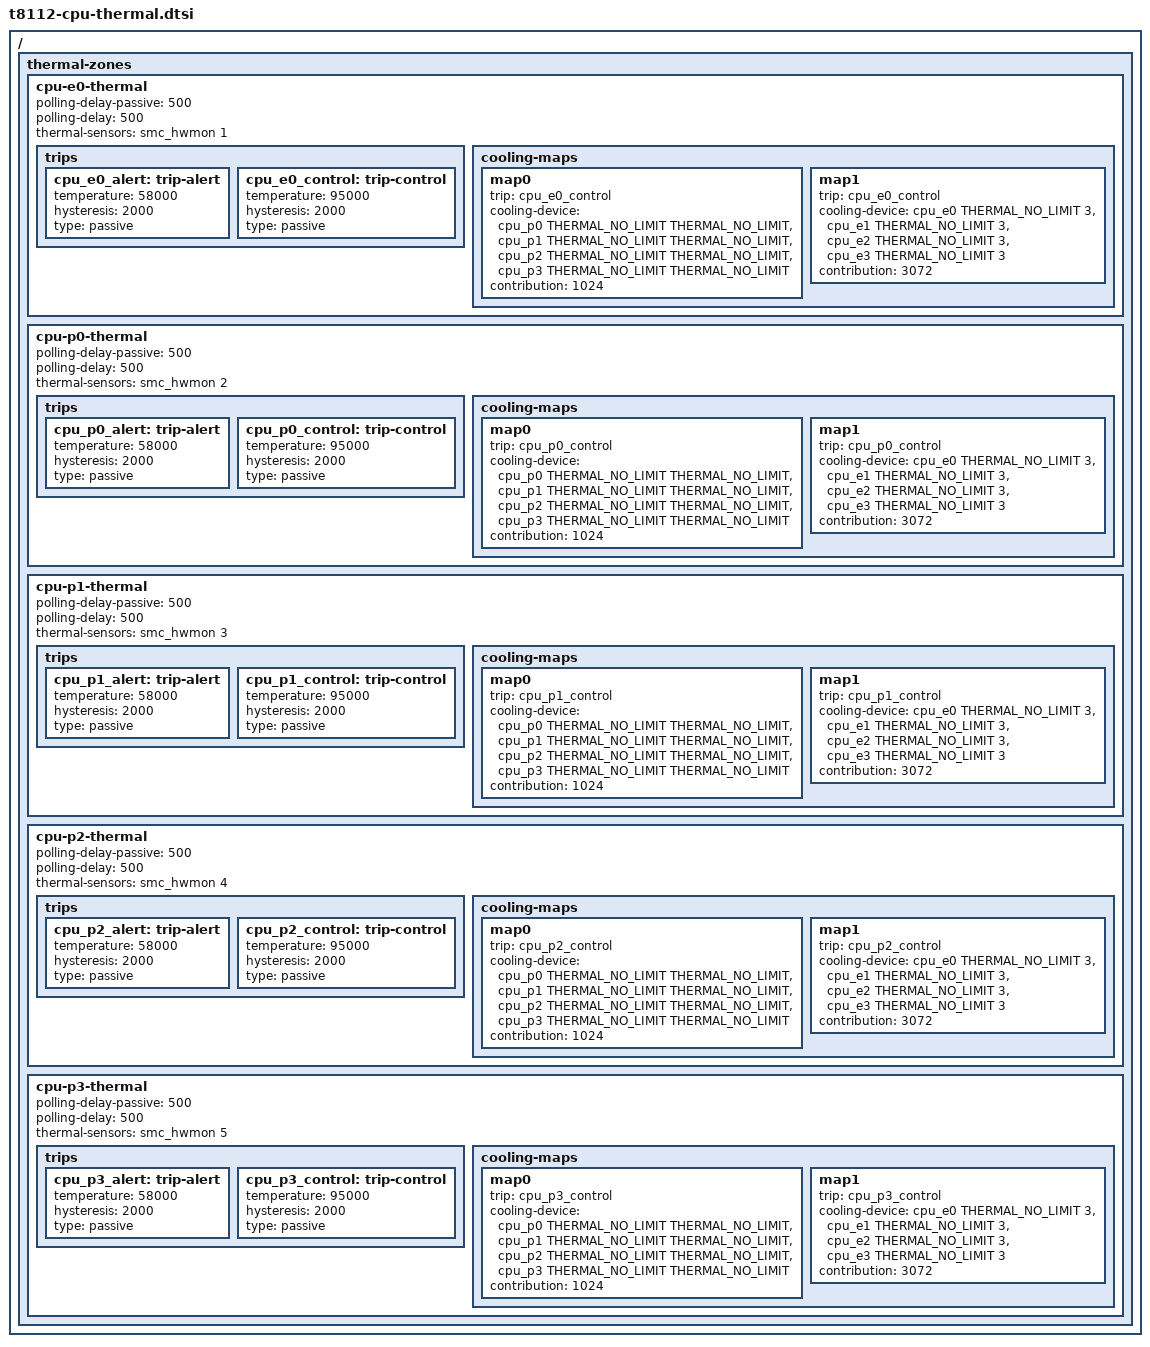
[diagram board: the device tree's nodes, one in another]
// SPDX-License-Identifier: GPL-2.0+ OR MIT
/*
 * CPU thermal zones of the fanless T8112 (M2) MacBook Airs.
 *
 * Each zone reads one SoC die key from the SMC hwmon: the T8112 SMC
 * reports them on every board, so t8112.dtsi lists them first among the
 * temperature channels and their indices are the same on every T8112
 * board (1: Te05, 2: Tp01, 3: Tp05, 4: Tp09, 5: Tp0D). The CPUs are
 * cooling devices in t8112.dtsi.
 *
 * Every die sensor throttles both clusters, E weighted 3:1 and capped at
 * state 3, as on the J613, with its alert and control trips. No critical
 * trip: boot load bursts briefly read past 100 C, and the SMC keeps its
 * own protection.
 *
 * The alert trip suits a fanless chassis only: with a fan the die runs
 * above it under ordinary load, so the boards with a fan (J473, J493)
 * need their own trip set and do not include this file.
 *
 * sustainable-power depends on how much heat the chassis sheds, so it is
 * not set here: a board with a measured value sets it on each zone (see
 * t8112-j413.dts). Without it the power allocator estimates it from the
 * cooling devices' lowest allowed power (P cluster at its lowest
 * frequency, E at state 3), the most conservative budget: it holds the
 * CPUs down harder above the alert trip than a measured value would.
 *
 * Copyright The Asahi Linux Contributors
 */

#include <dt-bindings/thermal/thermal.h>

/ {
	thermal-zones {
		cpu-e0-thermal {
			polling-delay-passive = <500>;
			polling-delay = <500>;
			thermal-sensors = <&smc_hwmon 1>;	/* Te05 */

			trips {
				cpu_e0_alert: trip-alert {
					temperature = <58000>;
					hysteresis = <2000>;
					type = "passive";
				};

				cpu_e0_control: trip-control {
					temperature = <95000>;
					hysteresis = <2000>;
					type = "passive";
				};
			};

			cooling-maps {
				map0 {
					trip = <&cpu_e0_control>;
					cooling-device =
						<&cpu_p0 THERMAL_NO_LIMIT THERMAL_NO_LIMIT>,
						<&cpu_p1 THERMAL_NO_LIMIT THERMAL_NO_LIMIT>,
						<&cpu_p2 THERMAL_NO_LIMIT THERMAL_NO_LIMIT>,
						<&cpu_p3 THERMAL_NO_LIMIT THERMAL_NO_LIMIT>;
					contribution = <1024>;
				};

				map1 {
					trip = <&cpu_e0_control>;
					cooling-device =
						<&cpu_e0 THERMAL_NO_LIMIT 3>,
						<&cpu_e1 THERMAL_NO_LIMIT 3>,
						<&cpu_e2 THERMAL_NO_LIMIT 3>,
						<&cpu_e3 THERMAL_NO_LIMIT 3>;
					contribution = <3072>;
				};
			};
		};

		cpu-p0-thermal {
			polling-delay-passive = <500>;
			polling-delay = <500>;
			thermal-sensors = <&smc_hwmon 2>;	/* Tp01 */

			trips {
				cpu_p0_alert: trip-alert {
					temperature = <58000>;
					hysteresis = <2000>;
					type = "passive";
				};

				cpu_p0_control: trip-control {
					temperature = <95000>;
					hysteresis = <2000>;
					type = "passive";
				};
			};

			cooling-maps {
				map0 {
					trip = <&cpu_p0_control>;
					cooling-device =
						<&cpu_p0 THERMAL_NO_LIMIT THERMAL_NO_LIMIT>,
						<&cpu_p1 THERMAL_NO_LIMIT THERMAL_NO_LIMIT>,
						<&cpu_p2 THERMAL_NO_LIMIT THERMAL_NO_LIMIT>,
						<&cpu_p3 THERMAL_NO_LIMIT THERMAL_NO_LIMIT>;
					contribution = <1024>;
				};

				map1 {
					trip = <&cpu_p0_control>;
					cooling-device =
						<&cpu_e0 THERMAL_NO_LIMIT 3>,
						<&cpu_e1 THERMAL_NO_LIMIT 3>,
						<&cpu_e2 THERMAL_NO_LIMIT 3>,
						<&cpu_e3 THERMAL_NO_LIMIT 3>;
					contribution = <3072>;
				};
			};
		};

		cpu-p1-thermal {
			polling-delay-passive = <500>;
			polling-delay = <500>;
			thermal-sensors = <&smc_hwmon 3>;	/* Tp05 */

			trips {
				cpu_p1_alert: trip-alert {
					temperature = <58000>;
					hysteresis = <2000>;
					type = "passive";
				};

				cpu_p1_control: trip-control {
					temperature = <95000>;
					hysteresis = <2000>;
					type = "passive";
				};
			};

			cooling-maps {
				map0 {
					trip = <&cpu_p1_control>;
					cooling-device =
						<&cpu_p0 THERMAL_NO_LIMIT THERMAL_NO_LIMIT>,
						<&cpu_p1 THERMAL_NO_LIMIT THERMAL_NO_LIMIT>,
						<&cpu_p2 THERMAL_NO_LIMIT THERMAL_NO_LIMIT>,
						<&cpu_p3 THERMAL_NO_LIMIT THERMAL_NO_LIMIT>;
					contribution = <1024>;
				};

				map1 {
					trip = <&cpu_p1_control>;
					cooling-device =
						<&cpu_e0 THERMAL_NO_LIMIT 3>,
						<&cpu_e1 THERMAL_NO_LIMIT 3>,
						<&cpu_e2 THERMAL_NO_LIMIT 3>,
						<&cpu_e3 THERMAL_NO_LIMIT 3>;
					contribution = <3072>;
				};
			};
		};

		cpu-p2-thermal {
			polling-delay-passive = <500>;
			polling-delay = <500>;
			thermal-sensors = <&smc_hwmon 4>;	/* Tp09 */

			trips {
				cpu_p2_alert: trip-alert {
					temperature = <58000>;
					hysteresis = <2000>;
					type = "passive";
				};

				cpu_p2_control: trip-control {
					temperature = <95000>;
					hysteresis = <2000>;
					type = "passive";
				};
			};

			cooling-maps {
				map0 {
					trip = <&cpu_p2_control>;
					cooling-device =
						<&cpu_p0 THERMAL_NO_LIMIT THERMAL_NO_LIMIT>,
						<&cpu_p1 THERMAL_NO_LIMIT THERMAL_NO_LIMIT>,
						<&cpu_p2 THERMAL_NO_LIMIT THERMAL_NO_LIMIT>,
						<&cpu_p3 THERMAL_NO_LIMIT THERMAL_NO_LIMIT>;
					contribution = <1024>;
				};

				map1 {
					trip = <&cpu_p2_control>;
					cooling-device =
						<&cpu_e0 THERMAL_NO_LIMIT 3>,
						<&cpu_e1 THERMAL_NO_LIMIT 3>,
						<&cpu_e2 THERMAL_NO_LIMIT 3>,
						<&cpu_e3 THERMAL_NO_LIMIT 3>;
					contribution = <3072>;
				};
			};
		};

		cpu-p3-thermal {
			polling-delay-passive = <500>;
			polling-delay = <500>;
			thermal-sensors = <&smc_hwmon 5>;	/* Tp0D */

			trips {
				cpu_p3_alert: trip-alert {
					temperature = <58000>;
					hysteresis = <2000>;
					type = "passive";
				};

				cpu_p3_control: trip-control {
					temperature = <95000>;
					hysteresis = <2000>;
					type = "passive";
				};
			};

			cooling-maps {
				map0 {
					trip = <&cpu_p3_control>;
					cooling-device =
						<&cpu_p0 THERMAL_NO_LIMIT THERMAL_NO_LIMIT>,
						<&cpu_p1 THERMAL_NO_LIMIT THERMAL_NO_LIMIT>,
						<&cpu_p2 THERMAL_NO_LIMIT THERMAL_NO_LIMIT>,
						<&cpu_p3 THERMAL_NO_LIMIT THERMAL_NO_LIMIT>;
					contribution = <1024>;
				};

				map1 {
					trip = <&cpu_p3_control>;
					cooling-device =
						<&cpu_e0 THERMAL_NO_LIMIT 3>,
						<&cpu_e1 THERMAL_NO_LIMIT 3>,
						<&cpu_e2 THERMAL_NO_LIMIT 3>,
						<&cpu_e3 THERMAL_NO_LIMIT 3>;
					contribution = <3072>;
				};
			};
		};
	};
};
